# wsoc_uart_secure register map
Vendor: Texas Instruments
Peripheral module from a debugger description file (folder CC35X1E).
Registers are 32-bit, read-only, reset 0x0 unless marked. A register's access mark holds for its fields unless they carry their own. Offsets are as the file gives them; lines under a group give offsets from that group; [hi:lo] are bit positions; {n}, {i} and the like mark numbered series; 'fields as' and 'values as' point back to an identical list; <NAME> marks a mode.

## wsoc_uart_secure
0x00 uart_fifo wo
  [31:0] UART_DATA — UART TX buffer 8 bit data
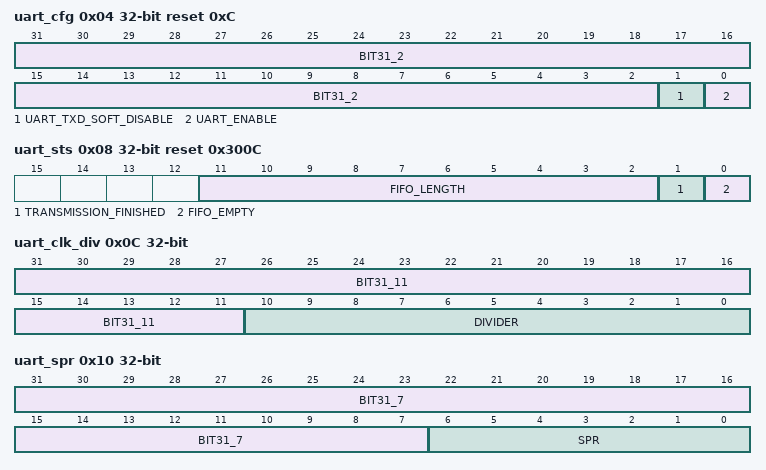
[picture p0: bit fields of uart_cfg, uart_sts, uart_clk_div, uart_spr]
0x04 uart_cfg access per field reset 0xC (reset mask 0xFFFFFFFC)
  [31:2] BIT31_2 ro — Reserved
  [1] UART_TXD_SOFT_DISABLE rw — soft disable 0: UART_TXD signal will be disabled immediately whenever uart_enable is cleared. 1: UART_TXD signal will be disabled only after stop bit whenever uart_enable is cleared. Note - when soft disable is 0 the Tx byte will be corupted when uart_enable is cleared. this mode is not recomanded.
  [0] UART_ENABLE rw — uart enable 0: UART TXD signal is disabled (from SW point of view the UART will be still working, just TXD signal on the output of the UART debug is disabled) 1: Enable TXD signal on the output of the UART debug. If enable command will be executed while the UART still has bytes to transmit, then the bytes will appear on the TXD line as soon as the command is executed.
0x08 uart_sts reset 0x300C (reset mask 0xFFFFFFFC) — UART_STATUS (UART_STS)
  [11:2] FIFO_LENGTH — Number of bytes at TX FIFO. Each write adds 4 bytes. Do not write more than 252 bytes (it will make the fifo empty).
  [1] TRANSMISSION_FINISHED — 1: The FIFO is empty And the last byte from the TX shift register is not being transmitted now. Clocks of the UART can be shut off. 0: The UART module is still transmitting the byte(s). (When FIFO_empty indicates that the FIFO is empty the last byte might still be transmitted shutting off the clock while this bit is "0" will cause a garbage data at the TXD line.
  [0] FIFO_EMPTY — Set when the FIFO is empty
0x0C uart_clk_div access per field reset not defined
  [31:11] BIT31_11 ro — Reserved
  [10:0] DIVIDER rw — Divide ratio of UART input clock. 0: no divide is needed (baud rate equal to UART input clock). 1: no divide is needed (baud rate equal to UART input clock). 2: divide UART clock by 2. 3: divide UART clock by 3. 2047: divide UART clock by 2047. This is the maximum number of the divider. Notice that the baud rate will be changed only after a full cycle of the old baud rate is completed.
0x10 uart_spr access per field reset not defined
  [31:7] BIT31_7 ro — Reserved
  [6:0] SPR rw — Sets the value of Swallowing Period Register. Uses in order to get the best accuracy at the baud rate of the UART_debug. When the value is 0 the Clock Swallowing Machine will be disabled. Notice that the baud rate will be changed only after a full cycle of the old baud rate is completed.
0x14 uart_wr_ptr_set wo — wr ptr set value. will update the write pointer of the fifo.
  [7:0] WR_PTR_SET_REG — write pointer set value
0x18 uart_rd_ptr_set wo — rd ptr set value. will update the read pointer of the fifo.
  [7:0] RD_PTR_SET_REG — read pointer set value
0x1C uart_wr_ptr_val — read value of current write pointer.
  [7:0] WR_PTR — write pointer current value
0x20 uart_rd_ptr_val — read value of current read pointer.
  [7:0] RD_PTR — read pointer current value
